# AE302F40C1537LE_CM55_HE_View register map
Vendor: Alif Semiconductor; Series: E3; File version: 1.0
CPU: CM55 r1p0, selectable endian, MPU, FPU, double-precision FPU, DSP, VTOR, 8 interrupt priority bits, 1 SAU regions
Registers are 32-bit, read-write, reset 0x0 unless marked. A register's access mark holds for its fields unless they carry their own. Offsets are from the block's base; [hi:lo] are bit positions; {n}, {i} and the like mark numbered series.

## LPI2C
Base 0x43009000
0x00 LPI2C_DATA — Read/Write Data Register
  [7:0] DATA — If the corresponding FIFO is not empty/full, a byte of data can be read/written to this address. From FIFO's perspective, it would be like a pop/push operation.
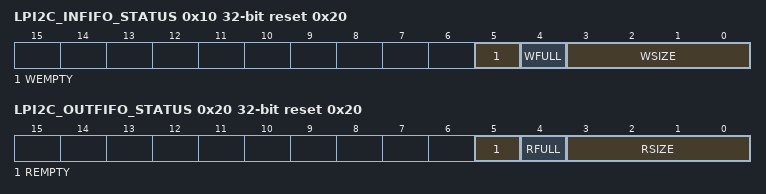
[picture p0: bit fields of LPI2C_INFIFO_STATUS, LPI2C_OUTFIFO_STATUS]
0x10 LPI2C_INFIFO_STATUS ro reset 0x20 — Inbound FIFO Status Register
  [5] WEMPTY — This field shows if the inbound FIFO is empty.
    0=Not empty; 1=Empty
  [4] WFULL — This field shows if the inbound FIFO is full.
    0=Not full; 1=Full
  [3:0] WSIZE — This field shows the number of available bytes of data in the inbound FIFO.
0x20 LPI2C_OUTFIFO_STATUS ro reset 0x20 — Outbound FIFO Status Register
  [5] REMPTY — This field shows if the outbound FIFO is empty.
    0=Not empty; 1=Empty
  [4] RFULL — This field shows if the outbound FIFO is full.
    0=Not full; 1=Full
  [3:0] RSIZE — This field shows the number of bytes of data in the outbound FIFO to be transmitted.

## CRC0
Base 0x48107000
Same registers: CRC1 0x48108000
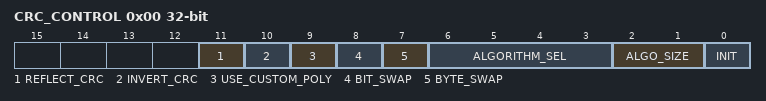
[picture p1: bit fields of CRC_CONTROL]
0x00 CRC_CONTROL — CRC Calculation Setup Register
  [11] REFLECT_CRC — Reflection of the CRC result as it is read out. An 8-bit CRC value is reflected on [7-0], bit7 to bit0, bit6 to bit1, etc. 16-bit and 32-bit CRC are reflected similarly.
    0=Reflection is disabled; 1=Reflection is enabled
  [10] INVERT_CRC — Inverting of each bit of the calculated CRC as it is read out.
    0=The CRC is not inverted; 1=Each bit is inverted
  [9] USE_CUSTOM_POLY — Use of a custom polynomial for CRC calculations. Note: Custom polynomials can only be used for 32-bit CRC algorithms.
    0=Custom polynomial is not used. The algorithm selected in CRC_CONTROL[ALGORITHM_SEL] bit field is used for the CRC calculation.; 1=Enable the use of a custom polynomial. For more information of the supported polynomials and their format, see Section CRC Overview and Section CRC Polynomials.
  [8] BIT_SWAP — Bit swapping during CRC calculation.
    0=Do not swap bits; 1=Swap the bits within each byte
  [7] BYTE_SWAP — Byte swapping during CRC calculation.
    0=Do not swap bytes; 1=Swap the bytes within each word (16-bit and 32-bit calculations only)
  [6:3] ALGORITHM_SEL — Algorithm selection.
    0=CRC-8-CCITT; 2=CRC-16; 3=CRC-16-CCITT; 4=CRC-32; 5=CRC-32C
  [2:1] ALGO_SIZE — Algorithm size selection. Must program CRC_CONTROL[ALGO_SIZE] = 0x2 when using custom polynomials.
    0=8-bit; 1=16-bit; 2=32-bit
  [0] INIT — Writing INIT will load seed and polynomial. Reading will always return INIT = 0. Bit must always be written to 0x1 before starting CRC calculations.
0x10 CRC_SEED reset 0xFFFFFFFF — Seed Value Register
  [31:0] SEED — Seed value.
0x14 CRC_POLY_CUSTOM — Custom Polynomial Register
  [31:0] CRC_POLY_CUSTOM — Bits 31-0 are used for custom 32-bit CRC calculations.
0x18 CRC_OUT ro — Accumulated CRC Register
  [31:0] CRC_OUT — Bits 31-0 are used for reading out 32-bit CRC calculations. Bits 15-0 are used for reading out 16-bit CRCs. Lowest eight bits 7-0 are used for reading out 8-bit CRCs.
{0x20+i} CRC_DATA_IN_8_[{i}] (i=0..63) 8-bit wo reset not defined — 8-bit Values Register n
  [7:0] CRC_DATA_IN_8 — Data written in this register is for 8-bit and 16-bit calculations, but only 8-bits can be written per beat.
{0x60+4i} CRC_DATA_IN_32_[{i}] (i=0..39) wo reset not defined — 32-bit Values Register n
  [31:0] CRC_DATA_IN_32 — Data written in this register is for 32-bit calculations.

## DAC120
Base 0x49028000
Same registers: DAC121 0x49029000
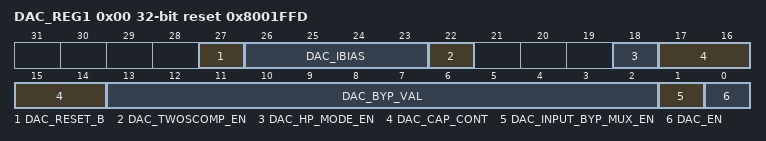
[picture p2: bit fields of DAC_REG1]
0x00 DAC_REG1 reset 0x8001FFD (reset mask 0xF8783FFF) — REG1 DAC Control Register
  [27] DAC_RESET_B — DAC reset:
    0=Reset asserted; 1=Reset released
  [26:23] DAC_IBIAS — Trims buffer output current (HP mode): From 0000 = 0 uA to 1111 = 1.5 mA Default is 1111 for DAC120 and 0000 for DAC121 Step size ~100 uA
  [22] DAC_TWOSCOMP_EN — Converts two's complement to unsigned binary data:
    0=Input data is unsigned; 1=Input data is two's complement signed (conversion to unsigned enable)
  [18] DAC_HP_MODE_EN — DAC high-performance mode enable.
    0=Low-power (LP) mode (default for DAC121); 1=High-performance (HP) mode (default for DAC120)
  [17:14] DAC_CAP_CONT — Trims HP mode capacitance compensation: From xx00 = 2 pF to xx11 = 8 pF Step size = 2 pF Default is xx11 = 8 pF for DAC120 and xx00 for DAC121 Bits [17-16] = Don't care
  [13:2] DAC_BYP_VAL — DAC input data in bypass mode
  [1] DAC_INPUT_BYP_MUX_EN — Selects DAC input data source:
    0=DAC_IN register; 1=DAC_REG1[DAC_BYP_VAL] bitfield (bypass mode)
  [0] DAC_EN — DAC enable:
    0=DAC is disabled; 1=DAC is enabled
0x04 DAC_IN — DAC Input Value Register
  [11:0] VALUE — Value used by DAC analog portion for conversion.
